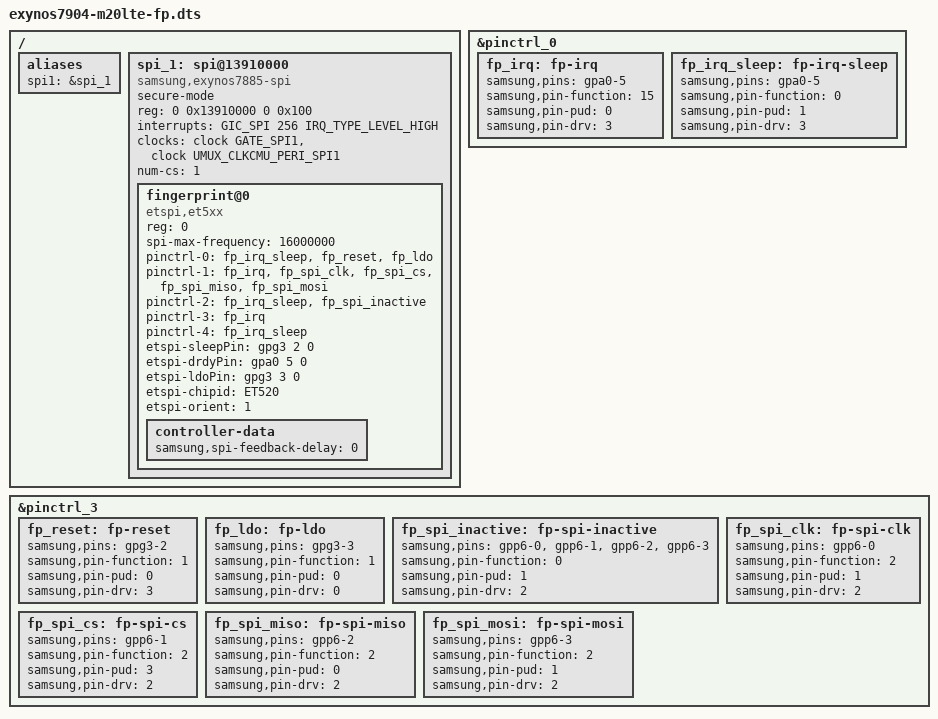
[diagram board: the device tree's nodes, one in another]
// SPDX-License-Identifier: GPL-2.0
/* M20 fingerprint bring-up variant. */
#include "exynos7904-m20lte.dts"

/* Fingerprint pins and wiring from the vendor m20lte sensor overlay. */
&pinctrl_0 {
	fp_irq: fp-irq {
		samsung,pins = "gpa0-5";
		samsung,pin-function = <15>;
		samsung,pin-pud = <0>;
		samsung,pin-drv = <3>;
	};
	fp_irq_sleep: fp-irq-sleep {
		samsung,pins = "gpa0-5";
		samsung,pin-function = <0>;
		samsung,pin-pud = <1>;
		samsung,pin-drv = <3>;
	};
};

&pinctrl_3 {
	fp_reset: fp-reset {
		samsung,pins = "gpg3-2";
		samsung,pin-function = <1>;
		samsung,pin-pud = <0>;
		samsung,pin-drv = <3>;
	};
	fp_ldo: fp-ldo {
		samsung,pins = "gpg3-3";
		samsung,pin-function = <1>;
		samsung,pin-pud = <0>;
		samsung,pin-drv = <0>;
	};
	fp_spi_inactive: fp-spi-inactive {
		samsung,pins = "gpp6-0", "gpp6-1", "gpp6-2", "gpp6-3";
		samsung,pin-function = <0>;
		samsung,pin-pud = <1>;
		samsung,pin-drv = <2>;
	};
	fp_spi_clk: fp-spi-clk {
		samsung,pins = "gpp6-0";
		samsung,pin-function = <2>;
		samsung,pin-pud = <1>;
		samsung,pin-drv = <2>;
	};
	fp_spi_cs: fp-spi-cs {
		samsung,pins = "gpp6-1";
		samsung,pin-function = <2>;
		samsung,pin-pud = <3>;
		samsung,pin-drv = <2>;
	};
	fp_spi_miso: fp-spi-miso {
		samsung,pins = "gpp6-2";
		samsung,pin-function = <2>;
		samsung,pin-pud = <0>;
		samsung,pin-drv = <2>;
	};
	fp_spi_mosi: fp-spi-mosi {
		samsung,pins = "gpp6-3";
		samsung,pin-function = <2>;
		samsung,pin-pud = <1>;
		samsung,pin-drv = <2>;
	};
};

/ {
	aliases {
		spi1 = &spi_1;
	};

	spi_1: spi@13910000 {
		secure-mode;
		compatible = "samsung,exynos7885-spi";
		reg = <0 0x13910000 0 0x100>;
		interrupts = <GIC_SPI 256 IRQ_TYPE_LEVEL_HIGH>;
		clocks = <&clock GATE_SPI1>, <&clock UMUX_CLKCMU_PERI_SPI1>;
		clock-names = "spi", "spi_busclk0";
		#address-cells = <1>;
		#size-cells = <0>;
		num-cs = <1>;
		status = "okay";
		fingerprint@0 {
			compatible = "etspi,et5xx";
			reg = <0>;
			spi-max-frequency = <16000000>;
			pinctrl-names = "default", "pins_poweron", "pins_poweroff", "pins_poweron_tz", "pins_poweroff_tz";
			pinctrl-0 = <&fp_irq_sleep &fp_reset &fp_ldo>;
			pinctrl-1 = <&fp_irq &fp_spi_clk &fp_spi_cs &fp_spi_miso &fp_spi_mosi>;
			pinctrl-2 = <&fp_irq_sleep &fp_spi_inactive>;
			pinctrl-3 = <&fp_irq>;
			pinctrl-4 = <&fp_irq_sleep>;
			etspi-sleepPin = <&gpg3 2 0>;
			etspi-drdyPin = <&gpa0 5 0>;
			etspi-ldoPin = <&gpg3 3 0>;
			etspi-chipid = "ET520";
			etspi-orient = <1>;
			controller-data {
				samsung,spi-feedback-delay = <0>;
			};
		};
	};
};
